# npck3m7k register map
Registers are 8-bit, read-write, no defined reset value unless marked. A register's access mark holds for its fields unless they carry their own. Offsets are from the block's base; [hi:lo] are bit positions; {n}, {i} and the like mark numbered series.

## FIU — Flash Interface Unit
Base 0x40020000
0x00 FIU_CFG
  [7:0] FL_SIZE
0x01 BURST_CFG
  [1:0] R_BURST
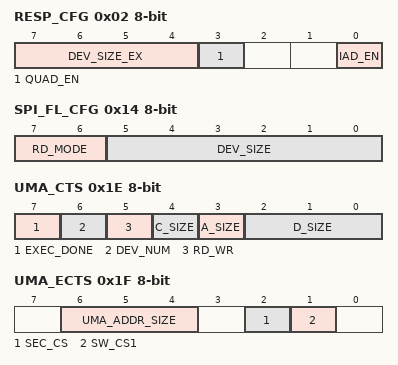
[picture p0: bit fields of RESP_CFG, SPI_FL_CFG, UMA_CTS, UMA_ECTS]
0x02 RESP_CFG
  [7:4] DEV_SIZE_EX, [3] QUAD_EN, [0] IAD_EN
0x14 SPI_FL_CFG
  [7:6] RD_MODE, [5:0] DEV_SIZE
0x16 UMA_CODE
{0x17+i} UMA_AB{i} (i=0..2)
{0x1A+i} UMA_DB{i} (i=0..3)
0x1E UMA_CTS
  [7] EXEC_DONE, [6] DEV_NUM, [5] RD_WR, [4] C_SIZE, [3] A_SIZE, [2:0] D_SIZE
0x1F UMA_ECTS
  [6:4] UMA_ADDR_SIZE, [2] SEC_CS, [1] SW_CS1
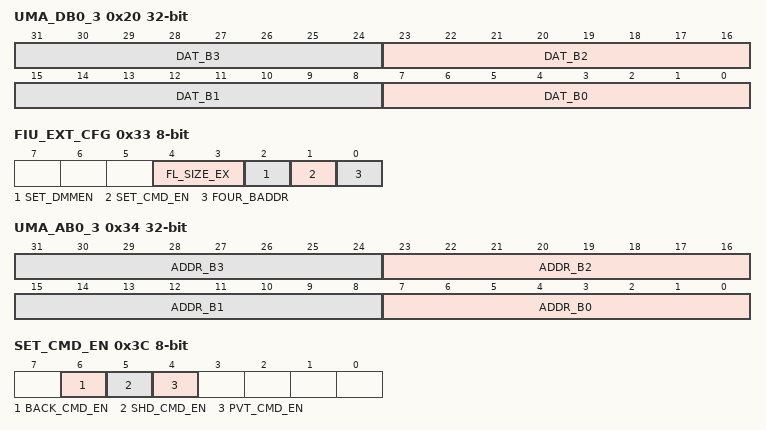
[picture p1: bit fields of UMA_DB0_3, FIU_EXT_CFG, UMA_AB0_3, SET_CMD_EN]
0x20 UMA_DB0_3 32-bit
  [8n+7:8n] DAT_B{n} (n=0..3)
0x2E RD_CMD_BACK
0x2F FIU_VER
0x30 RD_CMD_PVT
0x31 RD_CMD_SHD
0x32 FIU_DMM_CYC
  [4:0] DMM_CYC_NUM
0x33 FIU_EXT_CFG
  [4:3] FL_SIZE_EX, [2] SET_DMMEN, [1] SET_CMD_EN, [0] FOUR_BADDR
0x34 UMA_AB0_3 32-bit
  [8n+7:8n] ADDR_B{n} (n=0..3)
0x3C SET_CMD_EN
  [6] BACK_CMD_EN, [5] SHD_CMD_EN, [4] PVT_CMD_EN
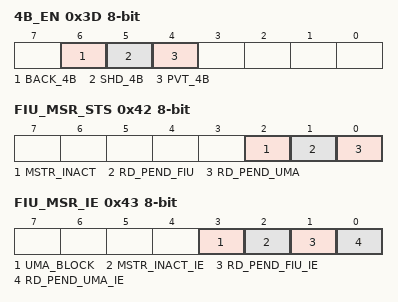
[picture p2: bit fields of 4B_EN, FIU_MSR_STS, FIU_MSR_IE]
0x3D 4B_EN
  [6] BACK_4B, [5] SHD_4B, [4] PVT_4B
0x40 FIU_ARB_THRSH
0x41 MI_CNT_THRSH
0x42 FIU_MSR_STS
  [2] MSTR_INACT, [1] RD_PEND_FIU, [0] RD_PEND_UMA
0x43 FIU_MSR_IE
  [3] UMA_BLOCK, [2] MSTR_INACT_IE, [1] RD_PEND_FIU_IE, [0] RD_PEND_UMA_IE

## FIU1 — Flash Interface Unit 1 (for eSPI)
Base 0x40021000
Registers as FIU, without FIU_CFG, FIU_VER, FIU_DMM_CYC, FIU_EXT_CFG, FIU_ARB_THRSH, FIU_MSR_STS, FIU_MSR_IE; these are added or differ:
0x00 FIU_CFG
  [7:0] FL_SIZE
0x2F FIU_VER
0x32 FIU_DMM_CYC
  [4:0] DMM_CYC_NUM
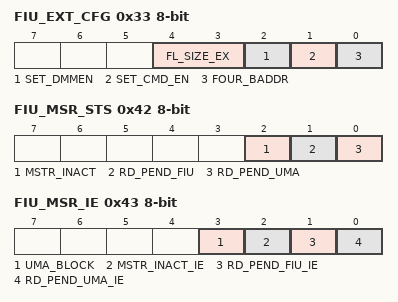
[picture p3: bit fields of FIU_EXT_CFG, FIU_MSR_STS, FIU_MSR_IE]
0x33 FIU_EXT_CFG
  [4:3] FL_SIZE_EX, [2] SET_DMMEN, [1] SET_CMD_EN, [0] FOUR_BADDR
0x40 FIU_ARB_THRSH
0x42 FIU_MSR_STS
  [2] MSTR_INACT, [1] RD_PEND_FIU, [0] RD_PEND_UMA
0x43 FIU_MSR_IE
  [3] UMA_BLOCK, [2] MSTR_INACT_IE, [1] RD_PEND_FIU_IE, [0] RD_PEND_UMA_IE

## HFCG — High-Frequency Clock Generator
Base 0x400B5000
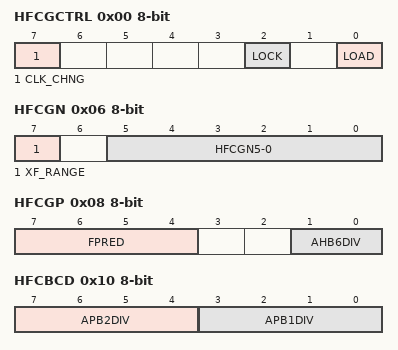
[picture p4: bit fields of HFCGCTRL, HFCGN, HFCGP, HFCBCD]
0x00 HFCGCTRL
  [7] CLK_CHNG, [2] LOCK, [0] LOAD
0x02 HFCGML
  [7:0] HFCGM7-0
0x04 HFCGMH
  [7:0] HFCGM15-8
0x06 HFCGN
  [7] XF_RANGE, [5:0] HFCGN5-0
0x08 HFCGP
  [7:4] FPRED, [1:0] AHB6DIV
0x0A HFCG_VER
  [3:0] HFCG_VER
0x10 HFCBCD
  [7:4] APB2DIV, [3:0] APB1DIV
0x12 HFCBCD1
  [1:0] FIUDIV
0x14 HFCBCD2
  [3:0] APB3DIV

## LFCG — Low-Frequency Clock Generator
Base 0x400B5100
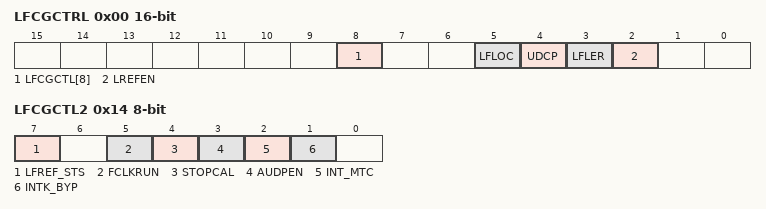
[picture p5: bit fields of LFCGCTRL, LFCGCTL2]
0x00 LFCGCTRL 16-bit
  [8] LFCGCTL[8], [5] LFLOC, [4] UDCP, [3] LFLER, [2] LREFEN
0x02 HFRDI 16-bit
  [11:0] HFRDI11-0
0x04 HFRDF 16-bit
  [15:0] HFRDF15-0
0x06 FRCDIV 16-bit
  [8:0] FRCDIV8-0
0x08 DIVMIN 16-bit
  [8:0] DIVMIN8-0
0x0A DIVMAX 16-bit
  [8:0] DIVMAX8-0
0x0E LFCG_VER
0x14 LFCGCTL2
  [7] LFREF_STS, [5] FCLKRUN, [4] STOPCAL, [3] AUDPEN, [2] INT_MTC, [1] INTK_BYP

## CR_UART — Core UART
Base 0x400C4000
0x00 UTBUF
0x02 URBUF
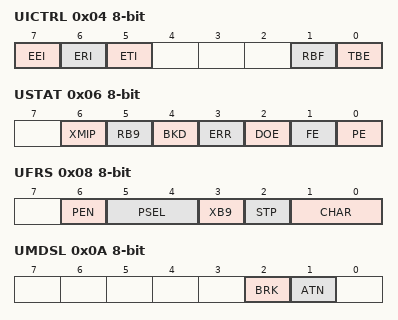
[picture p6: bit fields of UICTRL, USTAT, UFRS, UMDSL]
0x04 UICTRL
  [7] EEI, [6] ERI, [5] ETI, [1] RBF, [0] TBE
0x06 USTAT
  [6] XMIP, [5] RB9, [4] BKD, [3] ERR, [2] DOE, [1] FE, [0] PE
0x08 UFRS
  [6] PEN, [5:4] PSEL, [3] XB9, [2] STP, [1:0] CHAR
0x0A UMDSL
  [2] BRK, [1] ATN
0x0C UBAUD
  [7:0] UDIV7-0
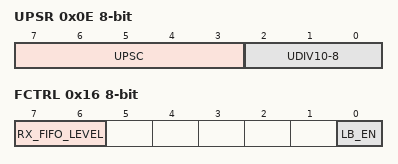
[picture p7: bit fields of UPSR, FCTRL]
0x0E UPSR
  [7:3] UPSC, [2:0] UDIV10-8
0x16 FCTRL
  [7:6] RX_FIFO_LEVEL, [0] LB_EN
0x18 TXFLV
  [4:0] TFL
0x1A RXFLV
  [4:0] RFL

## PECI — PECI Controller
Base 0x400D4000
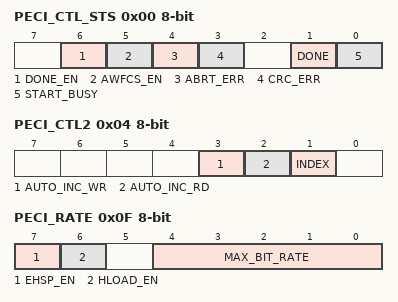
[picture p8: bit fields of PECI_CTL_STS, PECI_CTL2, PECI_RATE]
0x00 PECI_CTL_STS
  [6] DONE_EN, [5] AWFCS_EN, [4] ABRT_ERR, [3] CRC_ERR, [1] DONE, [0] START_BUSY
0x01 PECI_RD_LENGTH
  [4:0] READ_LENGTH
0x02 PECI_ADDR
0x03 PECI_CMD
0x04 PECI_CTL2
  [3] AUTO_INC_WR, [2] AUTO_INC_RD, [1] INDEX
0x05 PECI_INDEX
  [3:0] DATA_INDEX
0x06 PECI_IDATA
0x07 PECI_WR_LENGTH
  [4:0] WRITE_LENGTH
0x0B PECI_WR_FCS
0x0C PECI_RD_FCS
0x0D PECI_AW_FCS
0x0F PECI_RATE
  [7] EHSP_EN, [6] HLOAD_EN, [4:0] MAX_BIT_RATE
{0x10+i} PECI_DATA_IN_OUT{i} (i=0..9)
0x1A PECI_DATA_IN_OUTA
0x1B PECI_DATA_IN_OUTB
0x1C PECI_DATA_IN_OUTC
0x1D PECI_DATA_IN_OUTD
0x1E PECI_DATA_IN_OUTE
0x1F PECI_DATA_IN_OUTF

## ASC — Core Register Map for ASIF
Base 0x40012000
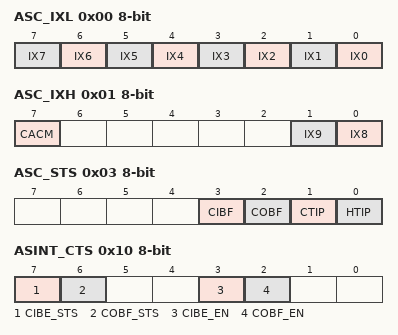
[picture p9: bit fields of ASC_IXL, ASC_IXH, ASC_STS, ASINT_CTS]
0x00 ASC_IXL
  [n] IX{n} (n=0..7)
0x01 ASC_IXH
  [7] CACM, [1] IX9, [0] IX8
0x02 ASC_DAT
  [7:0] DATA
0x03 ASC_STS
  [3] CIBF, [2] COBF, [1] CTIP, [0] HTIP
0x04 ASC_BAL
  [7:0] HBAL
0x05 ASC_BAH
  [7:0] HBAH
{0x6+i} ASC_SCR{i} (i=0..9)
  [7:0] SCRATCH{i}
0x10 ASINT_CTS
  [7] CIBE_STS, [6] COBF_STS, [3] CIBE_EN, [2] COBF_EN
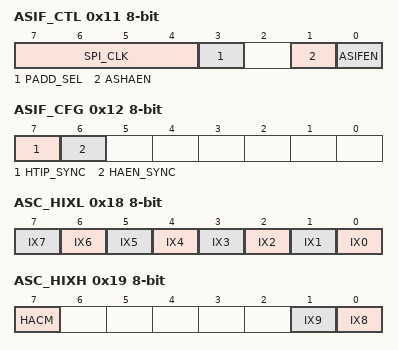
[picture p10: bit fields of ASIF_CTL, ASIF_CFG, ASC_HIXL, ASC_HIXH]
0x11 ASIF_CTL
  [7:4] SPI_CLK, [3] PADD_SEL, [1] ASHAEN, [0] ASIFEN
0x12 ASIF_CFG
  [7] HTIP_SYNC, [6] HAEN_SYNC
0x18 ASC_HIXL
  [n] IX{n} (n=0..7)
0x19 ASC_HIXH
  [7] HACM, [1] IX9, [0] IX8
0x1A ASC_HDAT
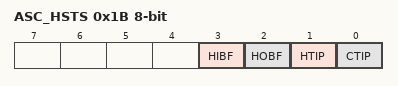
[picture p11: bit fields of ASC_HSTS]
0x1B ASC_HSTS
  [3] HIBF, [2] HOBF, [1] HTIP, [0] CTIP
